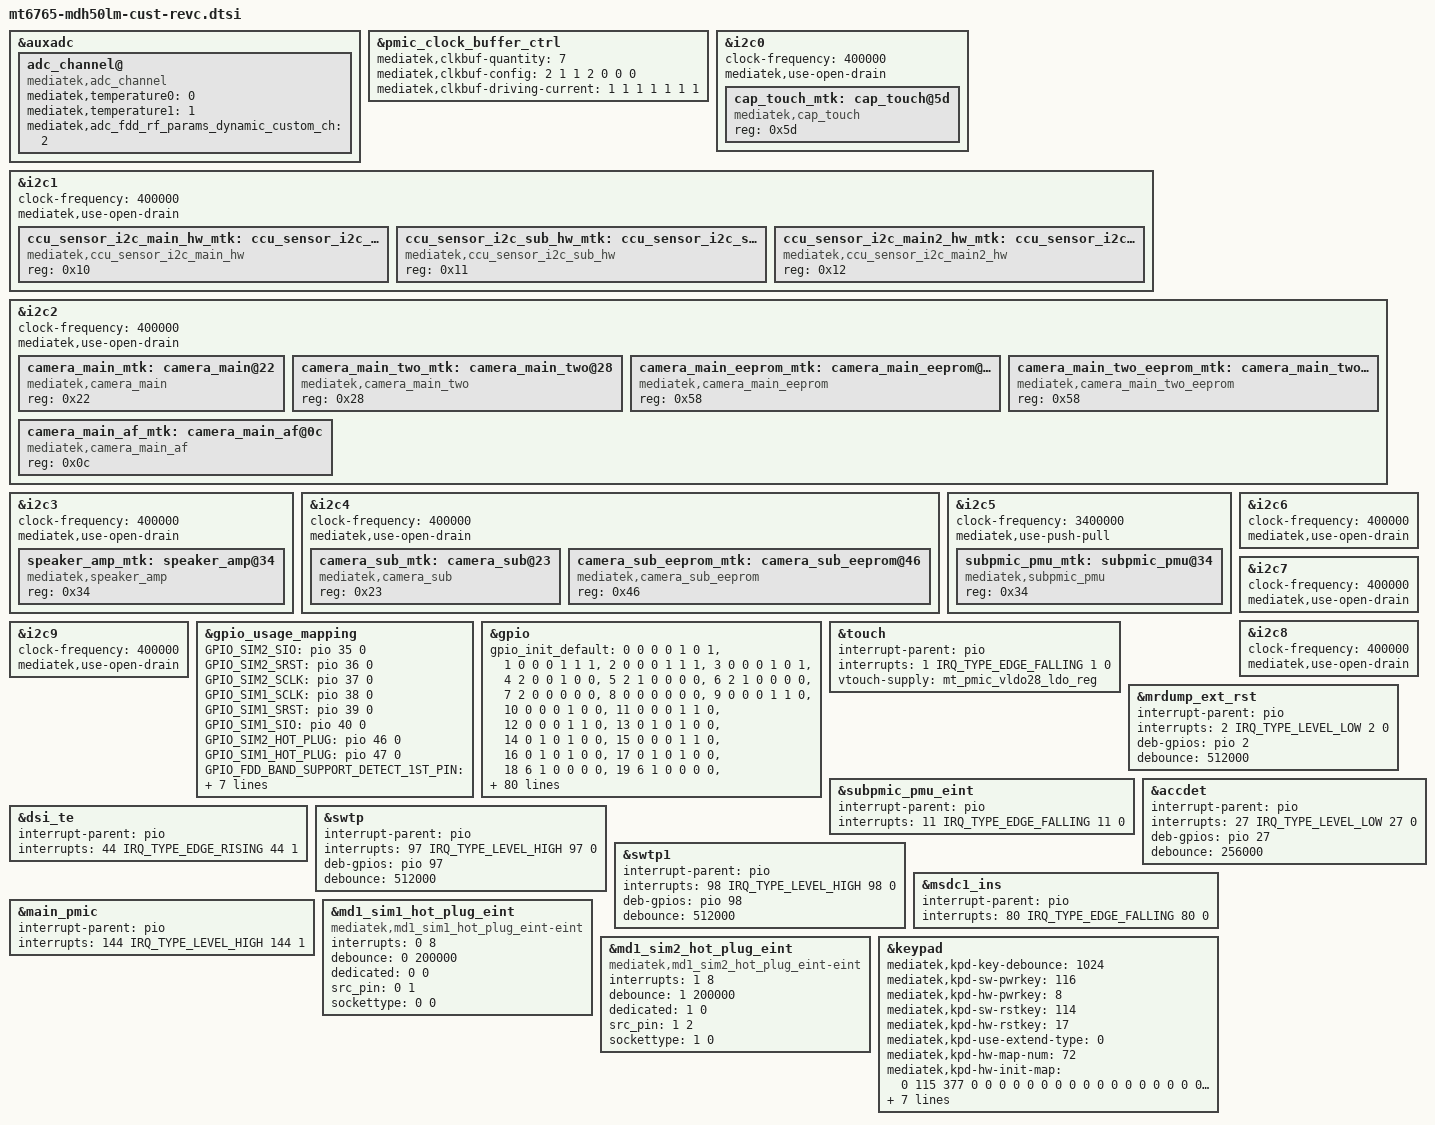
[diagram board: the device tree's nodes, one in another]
/*
 * Generated by MTK SP DrvGen Version: 3.5.160809 for MT6765.
 * 2019-11-06 00:45:47
 * Do Not Modify The File.
 * Copyright Mediatek Inc. (c) 2016.
*/

/*************************
 * ADC DTSI File
*************************/

&auxadc {
	adc_channel@ {
		compatible = "mediatek,adc_channel";
		mediatek,temperature0 = <0>;
		mediatek,temperature1 = <1>;
		mediatek,adc_fdd_rf_params_dynamic_custom_ch = <2>;
		status = "okay";
	};
};


/*************************
 * CLK_BUF DTSI File
*************************/

&pmic_clock_buffer_ctrl {
	mediatek,clkbuf-quantity = <7>;
	mediatek,clkbuf-config = <2 1 1 2 0 0 0>;
	mediatek,clkbuf-driving-current = <1 1 1 1 1 1 1>;
	status = "okay";
};


/*************************
 * I2C DTSI File
*************************/

&i2c0 {
	#address-cells = <1>;
	#size-cells = <0>;
	clock-frequency = <400000>;
	mediatek,use-open-drain;
	cap_touch_mtk:cap_touch@5d {
		compatible = "mediatek,cap_touch";
		reg = <0x5d>;
		status = "okay";
	};

};

&i2c1 {
	#address-cells = <1>;
	#size-cells = <0>;
	clock-frequency = <400000>;
	mediatek,use-open-drain;
	ccu_sensor_i2c_main_hw_mtk:ccu_sensor_i2c_main_hw@10 {
		compatible = "mediatek,ccu_sensor_i2c_main_hw";
		reg = <0x10>;
		status = "okay";
	};

	ccu_sensor_i2c_sub_hw_mtk:ccu_sensor_i2c_sub_hw@11 {
		compatible = "mediatek,ccu_sensor_i2c_sub_hw";
		reg = <0x11>;
		status = "okay";
	};

	ccu_sensor_i2c_main2_hw_mtk:ccu_sensor_i2c_main2_hw@12 {
		compatible = "mediatek,ccu_sensor_i2c_main2_hw";
		reg = <0x12>;
		status = "okay";
	};

};

&i2c2 {
	#address-cells = <1>;
	#size-cells = <0>;
	clock-frequency = <400000>;
	mediatek,use-open-drain;
	camera_main_mtk:camera_main@22 {
		compatible = "mediatek,camera_main";
		reg = <0x22>;
		status = "okay";
	};

	camera_main_two_mtk:camera_main_two@28 {
		compatible = "mediatek,camera_main_two";
		reg = <0x28>;
		status = "okay";
	};

	camera_main_eeprom_mtk:camera_main_eeprom@58 {
		compatible = "mediatek,camera_main_eeprom";
		reg = <0x58>;
		status = "okay";
	};

	camera_main_two_eeprom_mtk:camera_main_two_eeprom@58 {
		compatible = "mediatek,camera_main_two_eeprom";
		reg = <0x58>;
		status = "okay";
	};

	camera_main_af_mtk:camera_main_af@0c {
		compatible = "mediatek,camera_main_af";
		reg = <0x0c>;
		status = "okay";
	};

};

&i2c3 {
	#address-cells = <1>;
	#size-cells = <0>;
	clock-frequency = <400000>;
	mediatek,use-open-drain;
	speaker_amp_mtk:speaker_amp@34 {
		compatible = "mediatek,speaker_amp";
		reg = <0x34>;
		status = "okay";
	};

};

&i2c4 {
	#address-cells = <1>;
	#size-cells = <0>;
	clock-frequency = <400000>;
	mediatek,use-open-drain;
	camera_sub_mtk:camera_sub@23 {
		compatible = "mediatek,camera_sub";
		reg = <0x23>;
		status = "okay";
	};

	camera_sub_eeprom_mtk:camera_sub_eeprom@46 {
		compatible = "mediatek,camera_sub_eeprom";
		reg = <0x46>;
		status = "okay";
	};

};

&i2c5 {
	#address-cells = <1>;
	#size-cells = <0>;
	clock-frequency = <3400000>;
	mediatek,use-push-pull;
	subpmic_pmu_mtk:subpmic_pmu@34 {
		compatible = "mediatek,subpmic_pmu";
		reg = <0x34>;
		status = "okay";
	};

};

&i2c6 {
	#address-cells = <1>;
	#size-cells = <0>;
	clock-frequency = <400000>;
	mediatek,use-open-drain;
};

&i2c7 {
	#address-cells = <1>;
	#size-cells = <0>;
	clock-frequency = <400000>;
	mediatek,use-open-drain;
};

&i2c8 {
	#address-cells = <1>;
	#size-cells = <0>;
	clock-frequency = <400000>;
	mediatek,use-open-drain;
};

&i2c9 {
	#address-cells = <1>;
	#size-cells = <0>;
	clock-frequency = <400000>;
	mediatek,use-open-drain;
};



/*************************
 * GPIO DTSI File
*************************/

&gpio_usage_mapping {
	GPIO_SIM2_SIO = <&pio 35 0>;
	GPIO_SIM2_SRST = <&pio 36 0>;
	GPIO_SIM2_SCLK = <&pio 37 0>;
	GPIO_SIM1_SCLK = <&pio 38 0>;
	GPIO_SIM1_SRST = <&pio 39 0>;
	GPIO_SIM1_SIO = <&pio 40 0>;
	GPIO_SIM2_HOT_PLUG = <&pio 46 0>;
	GPIO_SIM1_HOT_PLUG = <&pio 47 0>;
	GPIO_FDD_BAND_SUPPORT_DETECT_1ST_PIN = <&pio 175 0>;
	GPIO_FDD_BAND_SUPPORT_DETECT_2ND_PIN = <&pio 174 0>;
	GPIO_FDD_BAND_SUPPORT_DETECT_3RD_PIN = <&pio 173 0>;
	GPIO_FDD_BAND_SUPPORT_DETECT_4TH_PIN = <&pio 172 0>;
};

&gpio{
	gpio_init_default = <0 0 0 0 1 0 1>,
		<1 0 0 0 1 1 1>,
		<2 0 0 0 1 1 1>,
		<3 0 0 0 1 0 1>,
		<4 2 0 0 1 0 0>,
		<5 2 1 0 0 0 0>,
		<6 2 1 0 0 0 0>,
		<7 2 0 0 0 0 0>,
		<8 0 0 0 0 0 0>,
		<9 0 0 0 1 1 0>,
		<10 0 0 0 1 0 0>,
		<11 0 0 0 1 1 0>,
		<12 0 0 0 1 1 0>,
		<13 0 1 0 1 0 0>,
		<14 0 1 0 1 0 0>,
		<15 0 0 0 1 1 0>,
		<16 0 1 0 1 0 0>,
		<17 0 1 0 1 0 0>,
		<18 6 1 0 0 0 0>,
		<19 6 1 0 0 0 0>,
		<20 6 1 0 0 0 0>,
		<21 1 0 0 1 0 0>,
		<22 1 1 0 0 0 0>,
		<23 1 1 0 0 0 0>,
		<24 1 1 0 0 0 0>,
		<25 0 1 0 1 0 0>,
		<26 0 1 1 1 1 0>,
		<27 0 0 0 1 1 0>,
		<28 0 1 0 1 0 0>,
		<29 1 1 0 0 0 1>,
		<30 1 0 0 1 1 1>,
		<31 1 0 0 1 1 1>,
		<32 1 0 0 1 1 1>,
		<33 1 0 0 1 1 1>,
		<34 1 0 0 1 1 1>,
		<35 1 0 0 1 1 0>,
		<36 1 1 0 0 0 0>,
		<37 1 1 0 0 0 0>,
		<38 1 1 0 0 0 0>,
		<39 1 1 0 0 0 0>,
		<40 1 0 0 1 1 0>,
		<41 4 0 0 1 1 0>,
		<42 0 1 0 1 0 0>,
		<43 1 1 0 0 0 0>,
		<44 1 0 0 1 0 0>,
		<45 0 1 0 1 0 0>,
		<46 1 0 0 1 1 0>,
		<47 1 0 0 0 0 0>,
		<48 1 0 0 1 1 0>,
		<49 1 0 0 1 1 0>,
		<50 1 0 0 1 1 0>,
		<51 1 0 0 1 1 0>,
		<52 1 1 0 1 0 0>,
		<53 1 1 0 1 0 0>,
		<54 1 1 0 1 0 0>,
		<55 1 1 0 1 0 0>,
		<56 1 1 0 1 0 0>,
		<57 1 1 0 1 0 0>,
		<58 0 0 0 0 0 0>,
		<59 1 0 0 1 0 0>,
		<60 1 0 0 1 0 0>,
		<61 1 0 0 1 0 0>,
		<62 1 0 0 1 0 0>,
		<63 1 0 0 1 0 0>,
		<64 1 0 0 1 0 0>,
		<65 2 1 0 0 0 0>,
		<66 2 1 0 0 0 0>,
		<67 1 0 0 1 0 0>,
		<68 1 0 0 1 0 0>,
		<69 1 1 0 1 0 0>,
		<70 1 1 0 1 0 0>,
		<71 1 1 0 0 0 0>,
		<72 1 1 0 0 0 0>,
		<73 1 1 0 1 0 0>,
		<74 1 1 0 1 0 0>,
		<75 1 1 0 1 0 0>,
		<76 1 1 0 1 0 0>,
		<77 1 1 0 1 0 0>,
		<78 1 1 0 1 0 0>,
		<79 1 1 0 0 0 0>,
		<80 0 0 0 1 1 0>,
		<81 1 0 0 1 1 0>,
		<82 1 0 0 1 1 0>,
		<83 1 0 0 1 1 0>,
		<84 1 0 0 1 1 0>,
		<85 1 1 0 1 0 0>,
		<86 1 1 0 1 0 0>,
		<87 0 1 0 0 0 0>,
		<88 1 1 0 0 0 1>,
		<89 0 1 0 1 0 0>,
		<90 0 1 0 1 0 0>,
		<91 5 0 0 1 1 0>,
		<92 0 0 0 0 0 0>,
		<93 1 0 0 1 1 0>,
		<94 1 0 0 1 1 0>,
		<95 1 0 0 1 1 0>,
		<96 1 1 0 0 0 0>,
		<97 0 0 0 1 1 0>,
		<98 0 0 0 1 1 0>,
		<99 1 1 0 0 0 1>,
		<100 1 1 0 0 0 1>,
		<101 0 1 0 0 0 0>,
		<102 0 1 0 0 0 0>,
		<103 1 0 0 1 1 0>,
		<104 1 0 0 1 1 0>,
		<105 1 0 0 1 1 0>,
		<106 1 0 0 1 1 0>,
		<107 0 1 0 1 0 0>,
		<108 1 1 0 0 0 1>,
		<109 0 1 0 0 0 0>,
		<110 1 0 0 1 0 0>,
		<111 1 0 0 1 0 0>,
		<112 1 1 0 1 0 0>,
		<113 0 1 0 0 0 0>,
		<114 0 1 0 0 0 0>,
		<115 0 1 0 0 0 0>,
		<116 0 1 0 0 0 0>,
		<117 0 1 0 0 0 0>,
		<118 0 1 0 0 0 0>,
		<119 0 1 0 0 0 0>,
		<120 0 1 0 0 0 0>,
		<121 0 1 0 0 0 0>,
		<122 1 0 0 1 1 1>,
		<123 1 0 0 1 1 1>,
		<124 1 1 0 0 0 1>,
		<125 1 0 0 1 1 1>,
		<126 1 0 0 1 1 1>,
		<127 1 0 0 1 1 1>,
		<128 1 0 0 1 1 1>,
		<129 1 0 0 1 1 1>,
		<130 1 0 0 1 1 1>,
		<131 1 0 0 1 0 1>,
		<132 1 0 0 1 1 1>,
		<133 1 1 1 0 0 1>,
		<134 1 0 0 1 0 1>,
		<135 1 1 0 0 0 0>,
		<136 1 1 0 0 0 0>,
		<137 1 1 0 0 0 0>,
		<138 1 1 0 0 0 0>,
		<139 1 1 0 0 0 0>,
		<140 1 0 0 1 0 0>,
		<141 1 0 0 1 0 0>,
		<142 1 0 0 1 0 0>,
		<143 1 0 0 1 0 0>,
		<144 1 0 0 1 0 0>,
		<145 1 1 1 0 0 0>,
		<146 1 0 0 1 0 0>,
		<147 1 1 0 0 0 0>,
		<148 1 1 0 0 0 0>,
		<149 1 1 0 0 0 0>,
		<150 3 1 0 1 1 0>,
		<151 3 1 0 0 0 0>,
		<152 3 1 0 1 1 0>,
		<153 0 0 0 0 0 0>,
		<154 0 1 1 0 0 0>,
		<155 1 0 0 1 0 0>,
		<156 1 1 1 0 0 0>,
		<157 1 0 0 1 0 0>,
		<158 1 1 0 0 0 0>,
		<159 0 1 1 0 0 0>,
		<160 0 1 0 1 0 0>,
		<161 1 0 0 1 1 0>,
		<162 1 0 0 1 1 0>,
		<163 0 0 0 0 0 0>,
		<164 0 1 0 1 0 0>,
		<165 0 0 0 0 0 0>,
		<166 0 1 0 1 0 0>,
		<167 0 1 0 1 0 0>,
		<168 0 1 0 1 0 0>,
		<169 0 1 0 1 0 0>,
		<170 0 1 0 1 0 0>,
		<171 0 1 0 1 0 0>,
		<172 0 0 0 0 0 0>,
		<173 0 0 0 0 0 0>,
		<174 0 0 0 0 0 0>,
		<175 0 0 0 0 0 0>,
		<176 0 0 0 0 0 0>,
		<177 0 0 0 0 0 0>,
		<178 0 1 0 0 0 0>,
		<179 0 0 0 1 0 0>;
};


/*************************
 * EINT DTSI File
*************************/

#include <dt-bindings/interrupt-controller/irq.h>
#include <dt-bindings/interrupt-controller/arm-gic.h>

&touch {
	interrupt-parent = <&pio>;
	interrupts = <1 IRQ_TYPE_EDGE_FALLING 1 0>;
	status = "okay";
};

&mrdump_ext_rst {
	interrupt-parent = <&pio>;
	interrupts = <2 IRQ_TYPE_LEVEL_LOW 2 0>;
	deb-gpios = <&pio 2 0>;
	debounce = <512000>;
	status = "okay";
};

&subpmic_pmu_eint {
	interrupt-parent = <&pio>;
	interrupts = <11 IRQ_TYPE_EDGE_FALLING 11 0>;
	status = "okay";
};

&accdet {
	interrupt-parent = <&pio>;
	interrupts = <27 IRQ_TYPE_LEVEL_LOW 27 0>;
	deb-gpios = <&pio 27 0>;
	debounce = <256000>;
	status = "okay";
};

&dsi_te {
	interrupt-parent = <&pio>;
	interrupts = <44 IRQ_TYPE_EDGE_RISING 44 1>;
	status = "okay";
};

&swtp {
	interrupt-parent = <&pio>;
	interrupts = <97 IRQ_TYPE_LEVEL_HIGH 97 0>;
	deb-gpios = <&pio 97 0>;
	debounce = <512000>;
	status = "okay";
};

&swtp1 {
	interrupt-parent = <&pio>;
	interrupts = <98 IRQ_TYPE_LEVEL_HIGH 98 0>;
	deb-gpios = <&pio 98 0>;
	debounce = <512000>;
	status = "okay";
};

&msdc1_ins {
	interrupt-parent = <&pio>;
	interrupts = <80 IRQ_TYPE_EDGE_FALLING 80 0>;
	status = "okay";
};

&main_pmic {
	interrupt-parent = <&pio>;
	interrupts = <144 IRQ_TYPE_LEVEL_HIGH 144 1>;
	status = "okay";
};



/*************************
 * MD1_EINT DTSI File
*************************/

&md1_sim1_hot_plug_eint {
	compatible = "mediatek,md1_sim1_hot_plug_eint-eint";
	interrupts = <0 8>;
	debounce = <0 200000>;
	dedicated = <0 0>;
	src_pin = <0 1>;
	sockettype = <0 0>;
	status = "okay";
};

&md1_sim2_hot_plug_eint {
	compatible = "mediatek,md1_sim2_hot_plug_eint-eint";
	interrupts = <1 8>;
	debounce = <1 200000>;
	dedicated = <1 0>;
	src_pin = <1 2>;
	sockettype = <1 0>;
	status = "okay";
};



/*************************
 * PMIC DTSI File
*************************/

&touch {
	vtouch-supply = <&mt_pmic_vldo28_ldo_reg>;
	status = "okay";
};



/*************************
 * POWER DTSI File
*************************/



/*************************
 * KPD DTSI File
*************************/

&keypad {
	mediatek,kpd-key-debounce = <1024>;
	mediatek,kpd-sw-pwrkey = <116>;
	mediatek,kpd-hw-pwrkey = <8>;
	mediatek,kpd-sw-rstkey  = <114>;
	mediatek,kpd-hw-rstkey = <17>;
	mediatek,kpd-use-extend-type = <0>;
	/*HW Keycode [0~71] -> Linux Keycode*/
	mediatek,kpd-hw-map-num = <72>;
	mediatek,kpd-hw-init-map = <0 115 377 0 0 0 0 0 0 0 0 0 0 0 0 0 0 0 0 0 0 0 0 0 0 0 0 0 0 0 0 0 0 0 0 0 0 0 0 0 0 0 0 0 0 0 0 0 0 0 0 0 0 0 0 0 0 0 0 0 0 0 0 0 0 0 0 0 0 0 0 0 >;
	mediatek,kpd-pwrkey-eint-gpio = <0>;
	mediatek,kpd-pwkey-gpio-din  = <0>;
	mediatek,kpd-hw-dl-key0 = <1>;
	mediatek,kpd-hw-dl-key1 = <17>;
	mediatek,kpd-hw-dl-key2 = <8>;
	mediatek,kpd-hw-recovery-key = <1>;
	mediatek,kpd-hw-factory-key = <17>;
	status = "okay";
};


